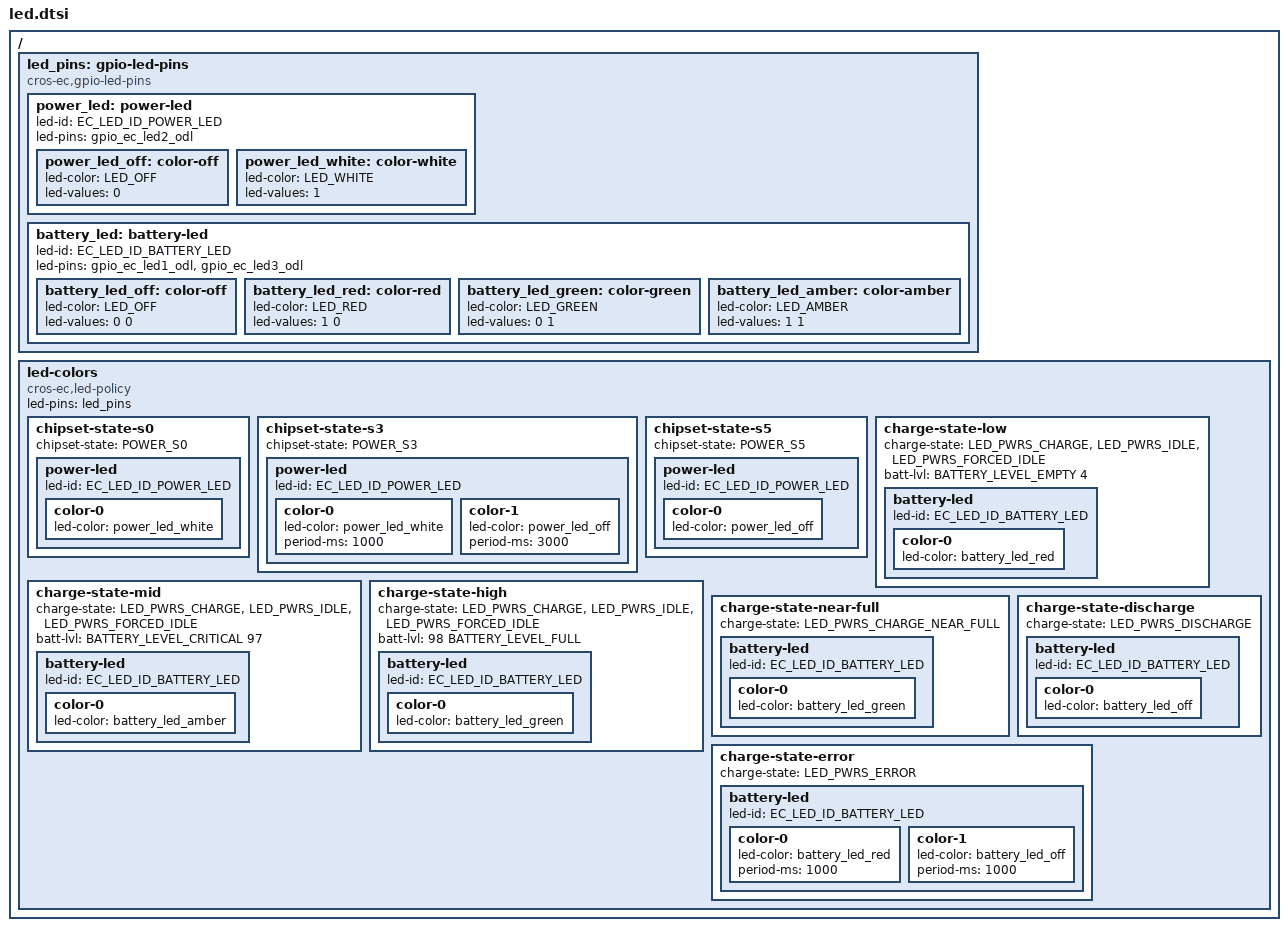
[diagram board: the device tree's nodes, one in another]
/* Copyright 2026 The ChromiumOS Authors
 * Use of this source code is governed by a BSD-style license that can be
 * found in the LICENSE file.
 */

#include <dt-bindings/battery.h>

/ {
	led_pins: gpio-led-pins {
		compatible = "cros-ec,gpio-led-pins";

		/* Power LED - white, on gpio_ec_led2_odl (GPIOC2) */
		power_led: power-led {
			led-id = "EC_LED_ID_POWER_LED";
			led-pins = <&gpio_ec_led2_odl>;

			power_led_off: color-off {
				led-color = "LED_OFF";
				led-values = <0>;
			};

			power_led_white: color-white {
				led-color = "LED_WHITE";
				led-values = <1>;
			};
		};

		battery_led: battery-led {
			led-id = "EC_LED_ID_BATTERY_LED";
			led-pins = <&gpio_ec_led1_odl &gpio_ec_led3_odl>;

			battery_led_off: color-off {
				led-color = "LED_OFF";
				led-values = <0 0>;
			};

			battery_led_red: color-red {
				led-color = "LED_RED";
				led-values = <1 0>;
			};

			battery_led_green: color-green {
				led-color = "LED_GREEN";
				led-values = <0 1>;
			};

			battery_led_amber: color-amber {
				led-color = "LED_AMBER";
				led-values = <1 1>;
			};
		};
	};

	led-colors {
		compatible = "cros-ec,led-policy";
		led-pins = <&led_pins>;

		/* ========== Power LED Policies ========== */

		/* S0: Power on - solid white */
		chipset-state-s0 {
			chipset-state = "POWER_S0";

			power-led {
				led-id = "EC_LED_ID_POWER_LED";
				color-0 {
					led-color = <&power_led_white>;
				};
			};
		};

		/* S3: Suspend - white breathing (1s on, 3s off) */
		chipset-state-s3 {
			chipset-state = "POWER_S3";

			power-led {
				led-id = "EC_LED_ID_POWER_LED";
				color-0 {
					led-color = <&power_led_white>;
					period-ms = <1000>;
				};
				color-1 {
					led-color = <&power_led_off>;
					period-ms = <3000>;
				};
			};
		};

		/* S5: Soft off - LED off */
		chipset-state-s5 {
			chipset-state = "POWER_S5";

			power-led {
				led-id = "EC_LED_ID_POWER_LED";
				color-0 {
					led-color = <&power_led_off>;
				};
			};
		};
		charge-state-low {
			charge-state = "LED_PWRS_CHARGE", "LED_PWRS_IDLE",
				"LED_PWRS_FORCED_IDLE";
			batt-lvl = <BATTERY_LEVEL_EMPTY 4>;

			battery-led {
				led-id = "EC_LED_ID_BATTERY_LED";
				color-0 {
					led-color = <&battery_led_red>;
				};
			};
		};

		charge-state-mid {
			charge-state = "LED_PWRS_CHARGE", "LED_PWRS_IDLE",
				"LED_PWRS_FORCED_IDLE";
			batt-lvl = <BATTERY_LEVEL_CRITICAL 97>;

			battery-led {
				led-id = "EC_LED_ID_BATTERY_LED";
				color-0 {
					led-color = <&battery_led_amber>;
				};
			};
		};

		charge-state-high {
			charge-state = "LED_PWRS_CHARGE", "LED_PWRS_IDLE",
				"LED_PWRS_FORCED_IDLE";
			batt-lvl = <98 BATTERY_LEVEL_FULL>;

			battery-led {
				led-id = "EC_LED_ID_BATTERY_LED";
				color-0 {
					led-color = <&battery_led_green>;
				};
			};
		};
		charge-state-near-full {
			charge-state = "LED_PWRS_CHARGE_NEAR_FULL";

			battery-led {
				led-id = "EC_LED_ID_BATTERY_LED";
				color-0 {
					led-color = <&battery_led_green>;
				};
			};
		};

		/* Discharging (no charger) - LED off */
		charge-state-discharge {
			charge-state = "LED_PWRS_DISCHARGE";

			battery-led {
				led-id = "EC_LED_ID_BATTERY_LED";
				color-0 {
					led-color = <&battery_led_off>;
				};
			};
		};

		/* Error (no battery, etc.) - solid amber */
		charge-state-error {
			charge-state = "LED_PWRS_ERROR";

			battery-led {
				led-id = "EC_LED_ID_BATTERY_LED";
				color-0 {
					led-color = <&battery_led_red>;
					period-ms = <1000>;
				};
				color-1 {
					led-color = <&battery_led_off>;
					period-ms = <1000>;
				};
			};
		};
	};
};
